# ING920 register map
Vendor: ARM Ltd.; Series: ARM Cortex M3; File version: 1.0
CPU: CM3 r2p1, little endian, MPU, no FPU, VTOR, 3 interrupt priority bits
Registers are 32-bit, read-write, reset 0x0 unless marked. A register's access mark holds for its fields unless they carry their own. Offsets are from the block's base; lines under a group give offsets from that group; [hi:lo] are bit positions; {n}, {i} and the like mark numbered series; 'fields as' and 'values as' point back to an identical list; <NAME> marks a mode.

## Memory map
0x40000000 sys_ctrl size 0x1000
0x40006000 PIN_MUX size 0x1000 — ping mux regiser
0x40015000 GPIO0 size 0x1000 — General purpose I/O
0x40016000 GPIO1 size 0x1000

## GPIO0 — General purpose I/O
Base 0x40015000
Same registers: GPIO1 0x40016000
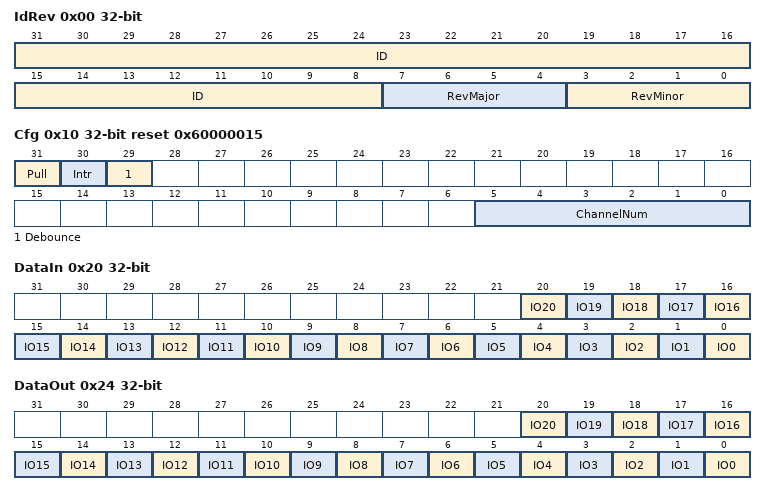
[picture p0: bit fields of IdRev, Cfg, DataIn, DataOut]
0x00 IdRev ro — ID and revision register
  [31:8] ID — ID number for ATCGPIO100
  [7:4] RevMajor — Port n.0 configurationMajor revision number
  [3:0] RevMinor — Minor revision number
0x10 Cfg ro reset 0x60000015 — Configuration register
  [31] Pull — Interrupt option
  [30] Intr — De-bounce option
  [29] Debounce — Number of channels
  [5:0] ChannelNum — Number of channels
0x20 DataIn ro — Channel data-in register
  [n] IO{n} (n=0..20) — IO
0x24 DataOut — Channel data-out register
  [n] IO{n} (n=0..20) — IO
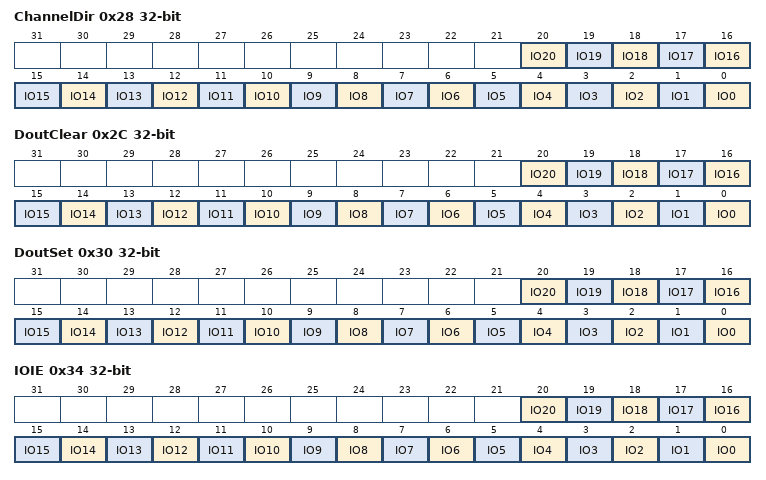
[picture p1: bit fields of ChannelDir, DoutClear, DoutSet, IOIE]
0x28 ChannelDir — Channel direction register
  [n] IO{n} (n=0..20) — IO
0x2C DoutClear wo — Channel data-out clear register
  [n] IO{n} (n=0..20) — IO
0x30 DoutSet wo — Channel data-out set register
  [n] IO{n} (n=0..20) — IO
0x34 IOIE — Interrupt enable register
  [n] IO{n} (n=0..20) — IO
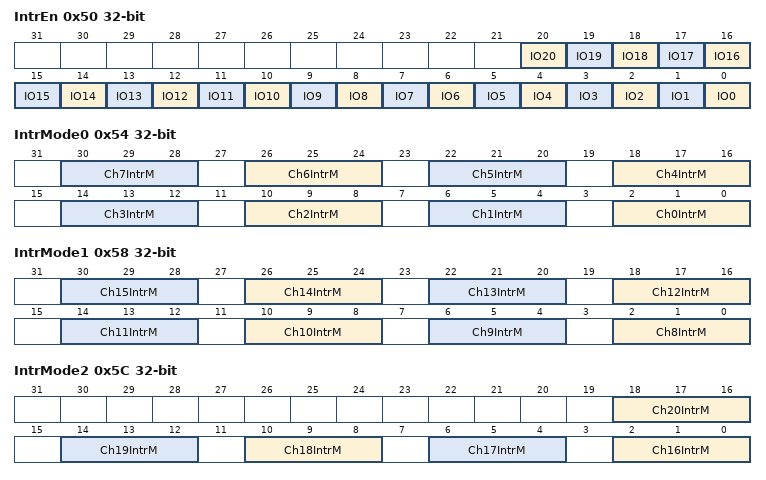
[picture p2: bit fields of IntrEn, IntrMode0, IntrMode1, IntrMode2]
0x50 IntrEn — Interrupt enable register
  [n] IO{n} (n=0..20) — IO
0x54 IntrMode0 — Interrupt mode register (0~7)
  [4n+2:4n] Ch{n}IntrM (n=0..7)
0x58 IntrMode1 — Interrupt mode register (8~15)
  [4n-30:4n-32] Ch{n}IntrM (n=8..15)
0x5C IntrMode2 — Interrupt mode register (16~23)
  [4n-62:4n-64] Ch{n}IntrM (n=16..20) — Ch{n-8}IntrM
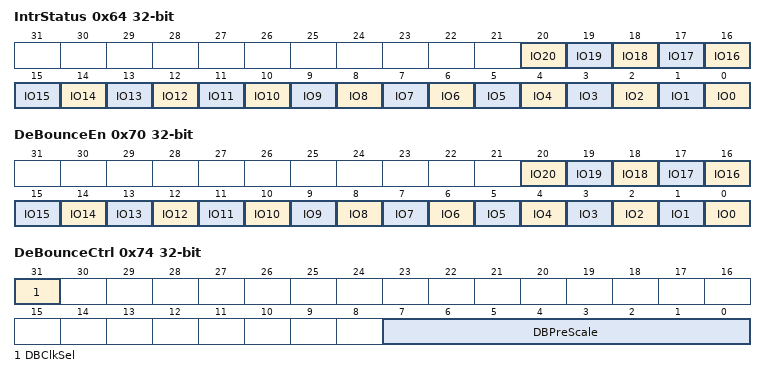
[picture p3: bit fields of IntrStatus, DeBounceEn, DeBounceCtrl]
0x64 IntrStatus — Interrupt status register
  [n] IO{n} (n=0..20) — IO
0x70 DeBounceEn — De-bounce enable register
  [n] IO{n} (n=0..20) — IO
0x74 DeBounceCtrl — De-bounce control register
  [31] DBClkSel, [7:0] DBPreScale

## sys_ctrl
Base 0x40000000
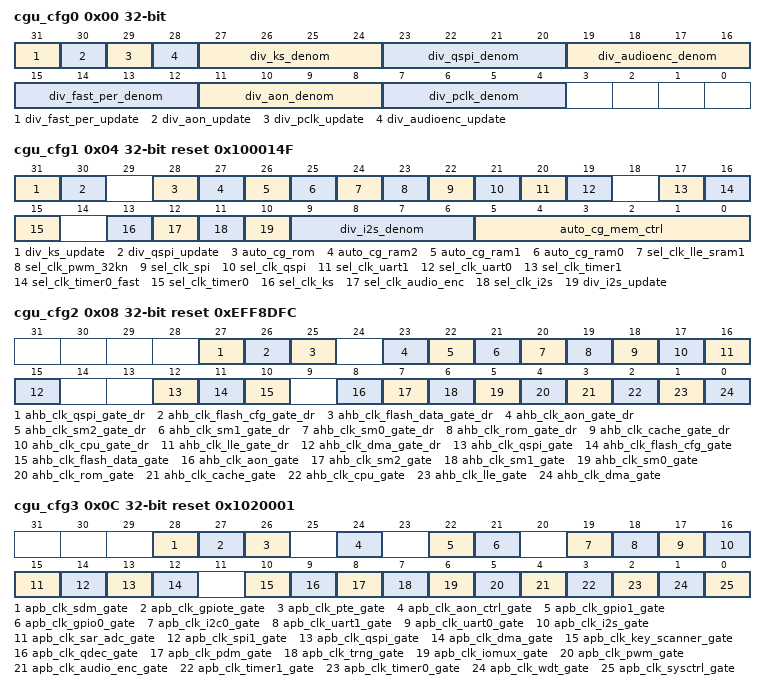
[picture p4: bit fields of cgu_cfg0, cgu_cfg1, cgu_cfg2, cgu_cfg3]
0x00 cgu_cfg0
  [31] div_fast_per_update, [30] div_aon_update, [29] div_pclk_update, [28] div_audioenc_update, [27:24] div_ks_denom, [23:20] div_qspi_denom, [19:16] div_audioenc_denom, [15:12] div_fast_per_denom, [11:8] div_aon_denom, [7:4] div_pclk_denom
0x04 cgu_cfg1 reset 0x100014F
  [31] div_ks_update, [30] div_qspi_update, [28] auto_cg_rom, [27] auto_cg_ram2, [26] auto_cg_ram1, [25] auto_cg_ram0, [24] sel_clk_lle_sram1, [23] sel_clk_pwm_32kn, [22] sel_clk_spi, [21] sel_clk_qspi, [20] sel_clk_uart1, [19] sel_clk_uart0, [17] sel_clk_timer1, [16] sel_clk_timer0_fast, [15] sel_clk_timer0, [13] sel_clk_ks, [12] sel_clk_audio_enc, [11] sel_clk_i2s, [10] div_i2s_update, [9:6] div_i2s_denom, [5:0] auto_cg_mem_ctrl
0x08 cgu_cfg2 reset 0xEFF8DFC
  [27] ahb_clk_qspi_gate_dr, [26] ahb_clk_flash_cfg_gate_dr, [25] ahb_clk_flash_data_gate_dr, [23] ahb_clk_aon_gate_dr, [22] ahb_clk_sm2_gate_dr, [21] ahb_clk_sm1_gate_dr, [20] ahb_clk_sm0_gate_dr, [19] ahb_clk_rom_gate_dr, [18] ahb_clk_cache_gate_dr, [17] ahb_clk_cpu_gate_dr, [16] ahb_clk_lle_gate_dr, [15] ahb_clk_dma_gate_dr, [12] ahb_clk_qspi_gate, [11] ahb_clk_flash_cfg_gate, [10] ahb_clk_flash_data_gate, [8] ahb_clk_aon_gate, [7] ahb_clk_sm2_gate, [6] ahb_clk_sm1_gate, [5] ahb_clk_sm0_gate, [4] ahb_clk_rom_gate, [3] ahb_clk_cache_gate, [2] ahb_clk_cpu_gate, [1] ahb_clk_lle_gate, [0] ahb_clk_dma_gate
0x0C cgu_cfg3 reset 0x1020001
  [28] apb_clk_sdm_gate, [27] apb_clk_gpiote_gate, [26] apb_clk_pte_gate, [24] apb_clk_aon_ctrl_gate, [22] apb_clk_gpio1_gate, [21] apb_clk_gpio0_gate, [19] apb_clk_i2c0_gate, [18] apb_clk_uart1_gate, [17] apb_clk_uart0_gate, [16] apb_clk_i2s_gate, [15] apb_clk_sar_adc_gate, [14] apb_clk_spi1_gate, [13] apb_clk_qspi_gate, [12] apb_clk_dma_gate, [10] apb_clk_key_scanner_gate, [9] apb_clk_qdec_gate, [8] apb_clk_pdm_gate, [7] apb_clk_trng_gate, [6] apb_clk_iomux_gate, [5] apb_clk_pwm_gate, [4] apb_clk_audio_enc_gate, [3] apb_clk_timer1_gate, [2] apb_clk_timer0_gate, [1] apb_clk_wdt_gate, [0] apb_clk_sysctrl_gate
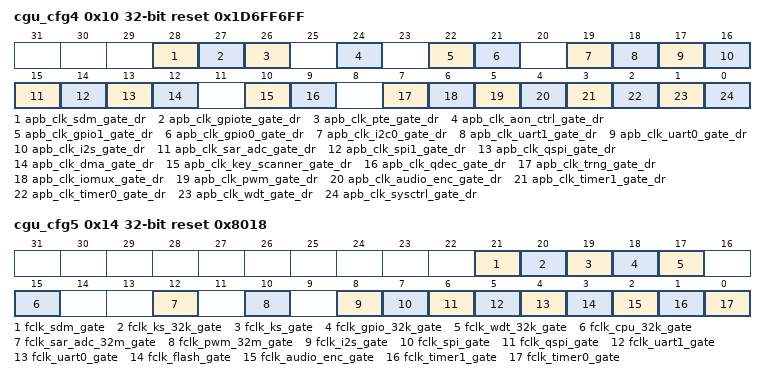
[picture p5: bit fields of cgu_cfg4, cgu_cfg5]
0x10 cgu_cfg4 reset 0x1D6FF6FF
  [28] apb_clk_sdm_gate_dr, [27] apb_clk_gpiote_gate_dr, [26] apb_clk_pte_gate_dr, [24] apb_clk_aon_ctrl_gate_dr, [22] apb_clk_gpio1_gate_dr, [21] apb_clk_gpio0_gate_dr, [19] apb_clk_i2c0_gate_dr, [18] apb_clk_uart1_gate_dr, [17] apb_clk_uart0_gate_dr, [16] apb_clk_i2s_gate_dr, [15] apb_clk_sar_adc_gate_dr, [14] apb_clk_spi1_gate_dr, [13] apb_clk_qspi_gate_dr, [12] apb_clk_dma_gate_dr, [10] apb_clk_key_scanner_gate_dr, [9] apb_clk_qdec_gate_dr, [7] apb_clk_trng_gate_dr, [6] apb_clk_iomux_gate_dr, [5] apb_clk_pwm_gate_dr, [4] apb_clk_audio_enc_gate_dr, [3] apb_clk_timer1_gate_dr, [2] apb_clk_timer0_gate_dr, [1] apb_clk_wdt_gate_dr, [0] apb_clk_sysctrl_gate_dr
0x14 cgu_cfg5 reset 0x8018
  [21] fclk_sdm_gate, [20] fclk_ks_32k_gate, [19] fclk_ks_gate, [18] fclk_gpio_32k_gate, [17] fclk_wdt_32k_gate, [15] fclk_cpu_32k_gate, [12] fclk_sar_adc_32m_gate, [10] fclk_pwm_32m_gate, [8] fclk_i2s_gate, [7] fclk_spi_gate, [6] fclk_qspi_gate, [5] fclk_uart1_gate, [4] fclk_uart0_gate, [3] fclk_flash_gate, [2] fclk_audio_enc_gate, [1] fclk_timer1_gate, [0] fclk_timer0_gate

## PIN_MUX — ping mux regiser
Base 0x40006000
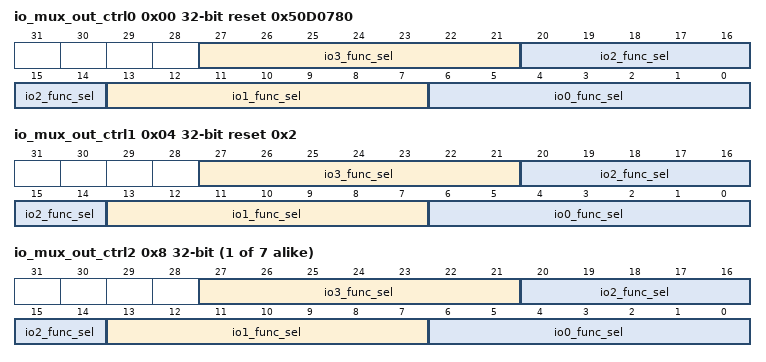
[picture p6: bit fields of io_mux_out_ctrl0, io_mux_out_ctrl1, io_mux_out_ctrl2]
0x00 io_mux_out_ctrl0 reset 0x50D0780
  [27:21] io3_func_sel — io0_func_sel
  [20:14] io2_func_sel — io0_func_sel
  [13:7] io1_func_sel — io0_func_sel
  [6:0] io0_func_sel
0x04 io_mux_out_ctrl1 reset 0x2
  fields as io_mux_out_ctrl0
{0x0+4i} io_mux_out_ctrl{i} (i=2..8)
  fields as io_mux_out_ctrl0
0x40 io_mux_in_ctrl0 reset 0x1FFFC64
  [31:0] sel
0x44 io_mux_in_ctrl1 reset 0xFFFFFF
  [31:0] sel
0x48 io_mux_in_ctrl2 reset 0xFFFFF
  [31:0] sel
0x4C io_mux_in_ctrl3 reset 0x1F17FF
  [31:0] sel
0x50 io_mux_in_ctrl4 reset 0xFE0FFFFF
  [31:0] sel
0x54 io_mux_in_ctrl5 reset 0x3FFFFFFF
  [31:0] sel
0x58 io_mux_in_ctrl6 reset 0xFFFFFFFF
  [31:0] sel
0x5C io_mux_in_ctrl7 reset 0x3F
  [31:0] sel
0x64 io_mux_in_ctrl9 reset 0x7FFFFFE0
  [31:0] sel
0x68 io_mux_in_ctrl10 reset 0x3FFFFFFF
  [31:0] sel
0x6C io_mux_in_ctrl11 reset 0x3FFFFFFF
  [31:0] sel
0x80 io_pe_ctrl0 reset 0x3801E
  [31:0] sel
0x84 io_pe_ctrl1
  [9:0] sel
0x88 io_ps_ctrl0 reset 0x1E
  [31:0] sel
0x8C io_ps_ctrl1
  [9:0] sel

## Licence text in the file
ARM Limited (ARM) is supplying this software for use with Cortex-M processor based microcontroller, but can be equally used for other suitable processor architectures. This file can be freely distributed. Modifications to this file shall be clearly marked. . THIS SOFTWARE IS PROVIDED "AS IS". NO WARRANTIES, WHETHER EXPRESS, IMPLIED. OR STATUTORY, INCLUDING, BUT NOT LIMITED TO, IMPLIED WARRANTIES OF. MERCHANTABILITY AND FITNESS FOR A PARTICULAR PURPOSE APPLY TO THIS SOFTWARE. ARM SHALL NOT, IN ANY CIRCUMSTANCES, BE LIABLE FOR SPECIAL, INCIDENTAL, OR. CONSEQUENTIAL DAMAGES, FOR ANY REASON WHATSOEVER.

## Notices in the file
Copyright (C) 2012 - 2018 Arm Limited. All rights reserved.
Purpose: System Viewer Description (SVD) Example (Schema Version 1.1)
This is a description of a none-existent and incomplete device
for demonstration purposes only.
Redistribution and use in source and binary forms, with or without
modification, are permitted provided that the following conditions are met:
- Redistributions of source code must retain the above copyright
notice, this list of conditions and the following disclaimer.
- Redistributions in binary form must reproduce the above copyright
notice, this list of conditions and the following disclaimer in the
documentation and/or other materials provided with the distribution.
- Neither the name of ARM nor the names of its contributors may be used
to endorse or promote products derived from this software without
specific prior written permission.
THIS SOFTWARE IS PROVIDED BY THE COPYRIGHT HOLDERS AND CONTRIBUTORS "AS IS"
AND ANY EXPRESS OR IMPLIED WARRANTIES, INCLUDING, BUT NOT LIMITED TO, THE
ARE DISCLAIMED. IN NO EVENT SHALL COPYRIGHT HOLDERS AND CONTRIBUTORS BE
LIABLE FOR ANY DIRECT, INDIRECT, INCIDENTAL, SPECIAL, EXEMPLARY, OR
CONSEQUENTIAL DAMAGES (INCLUDING, BUT NOT LIMITED TO, PROCUREMENT OF
SUBSTITUTE GOODS OR SERVICES; LOSS OF USE, DATA, OR PROFITS; OR BUSINESS
INTERRUPTION) HOWEVER CAUSED AND ON ANY THEORY OF LIABILITY, WHETHER IN
CONTRACT, STRICT LIABILITY, OR TORT (INCLUDING NEGLIGENCE OR OTHERWISE)
ARISING IN ANY WAY OUT OF THE USE OF THIS SOFTWARE, EVEN IF ADVISED OF THE
POSSIBILITY OF SUCH DAMAGE.
